# SAMA7G54D1G device description
Architecture: CORTEX-A7; Family: SAMA; Series: SAMA7G
Registers are 32-bit, read-write, reset 0x0 unless marked. A register's access mark holds for its fields unless they carry their own. Offsets are from the block's base; [hi:lo] are bit positions; {n}, {i} and the like mark numbered series.

## UHPHS — USB Host High Speed Port
Instances: UHPHS_EHCI 0x00500000
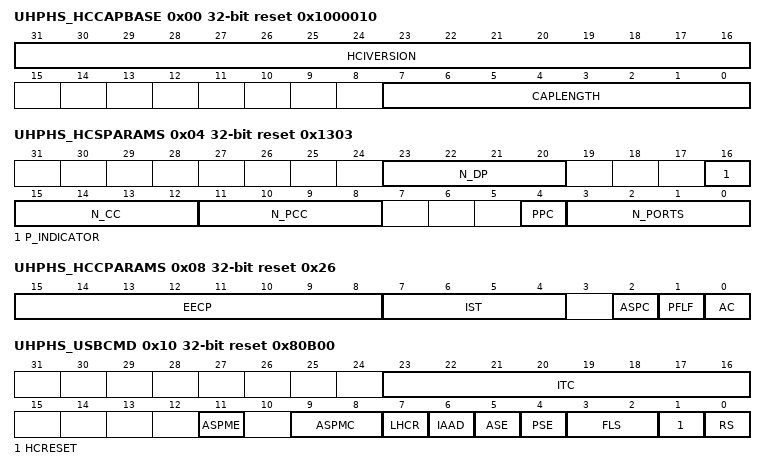
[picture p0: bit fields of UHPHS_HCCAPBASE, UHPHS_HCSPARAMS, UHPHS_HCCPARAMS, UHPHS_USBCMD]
0x00 UHPHS_HCCAPBASE ro reset 0x1000010 — UHPHS Host Controller Capability Register
  [31:16] HCIVERSION — Host Controller Interface Version Number
  [7:0] CAPLENGTH — Capability Registers Length
0x04 UHPHS_HCSPARAMS ro reset 0x1303 — UHPHS Host Controller Structural Parameters Register
  [23:20] N_DP — Debug Port Number
  [16] P_INDICATOR — Port Indicators
  [15:12] N_CC — Number of Companion Controllers
  [11:8] N_PCC — Number of Ports per Companion Controller
  [4] PPC — Port Power Control
  [3:0] N_PORTS — Number of Ports
0x08 UHPHS_HCCPARAMS ro reset 0x26 — UHPHS Host Controller Capability Parameters Register
  [15:8] EECP — EHCI Extended Capabilities Pointer
  [7:4] IST — Isochronous Scheduling Threshold
  [2] ASPC — Asynchronous Schedule Park Capability
    0=Host controller does not supports the park feature for high-speed queue; 1=Host controller supports the park feature for high-speed queue heads in the Asynchronous Schedule
  [1] PFLF — Programmable Frame List Flag
    0=System software must use a frame list length of 1024 elements with this host controller. The UHPHS_USBCMD register Frame List Size field is a read-only register and must be set to 0.; 1=System software can specify and use a smaller frame list and configure the host controller via the UHPHS_USBCMD register Frame List Size field. The frame list must always be aligned on a 4-Kbyte page boundary. This requirement ensures that the frame list is always physically contiguous.
  [0] AC — 64-bit Addressing Capability
    0=Data structures using 32-bit address memory pointers; 1=Data structures using 64-bit address memory pointers
0x10 UHPHS_USBCMD reset 0x80B00 — UHPHS USB Command Register
  [23:16] ITC — Interrupt Threshold Control (read/write)
  [11] ASPME — Asynchronous Schedule Park Mode Enable (optional) (read/write or read-only)
    0=Park mode is enabled; 1=Park mode is disabled
  [9:8] ASPMC — Asynchronous Schedule Park Mode Count (optional) (read/write or read-only)
  [7] LHCR — Light Host Controller Reset (optional) (read/write)
  [6] IAAD — Interrupt on Async Advance Doorbell (read/write)
  [5] ASE — Asynchronous Schedule Enable (read/write)
    0=Do not process the Asynchronous Schedule; 1=Use the UHPHS_ASYNCLISTADDR register to access the Asynchronous Schedule
  [4] PSE — Periodic Schedule Enable (read/write)
    0=Do not process the Periodic Schedule; 1=Use the UHPHS_PERIODICLISTBASE register to access the Periodic Schedule
  [3:2] FLS — Frame List Size (read/write or read-only)
    0=1024 elements (4096 bytes); 1=512 elements (2048 bytes); 2=256 elements (1024 bytes), for resource-constrained environments
  [1] HCRESET — Host Controller Reset (read/write)
  [0] RS — Run/Stop (read/write)
    0=Host Controller completes the current and any actively pipelined transactions on the USB and then halts; 1=Host Controller proceeds with execution of the schedule
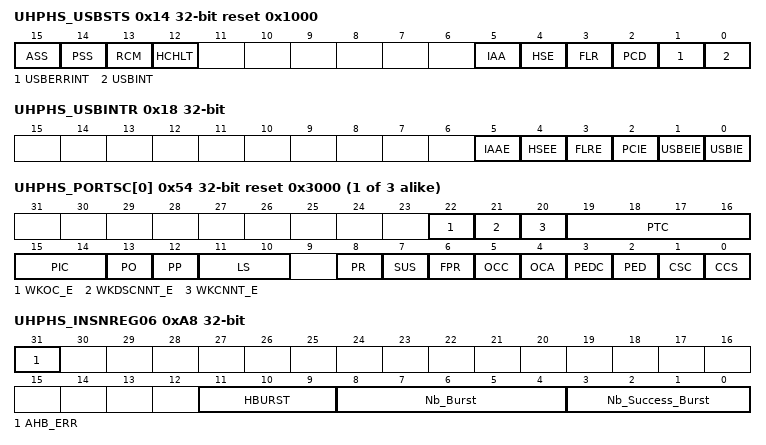
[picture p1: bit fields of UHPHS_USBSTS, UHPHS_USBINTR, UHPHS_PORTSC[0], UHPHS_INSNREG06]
0x14 UHPHS_USBSTS reset 0x1000 — UHPHS USB Status Register
  [15] ASS — Asynchronous Schedule Status (read-only)
    0=Asynchronous Schedule is disabled; 1=Asynchronous Schedule is enabled
  [14] PSS — Periodic Schedule Status (read-only)
  [13] RCM — Reclamation (read-only)
  [12] HCHLT — HCHalted (read-only)
  [5] IAA — Interrupt on Async Advance (cleared on write)
  [4] HSE — Host System Error (cleared on write)
  [3] FLR — Frame List Rollover (cleared on write)
  [2] PCD — Port Change Detect (cleared on write)
  [1] USBERRINT — USB Error Interrupt (cleared on write)
  [0] USBINT — USB Interrupt (cleared on write)
0x18 UHPHS_USBINTR — UHPHS USB Interrupt Enable Register
  [5] IAAE — Interrupt on Async Advance Enable
  [4] HSEE — Host System Error Interrupt Enable
  [3] FLRE — Frame List Rollover Interrupt Enable
  [2] PCIE — Port Change Detect Interrupt Enable
  [1] USBEIE — USBERRINT Interrupt Enable
  [0] USBIE — USBINT Interrupt Enable
0x1C UHPHS_FRINDEX — UHPHS USB Frame Index Register
  [13:0] FI — Frame Index
0x20 UHPHS_CTRLDSSEGMENT — UHPHS Control Data Structure Segment Register
0x24 UHPHS_PERIODICLISTBASE — UHPHS Periodic Frame List Base Address Register
  [31:12] BA — Base Address (Low)
0x28 UHPHS_ASYNCLISTADDR — UHPHS Asynchronous List Address Register
  [31:5] LPL — Link Pointer Low
0x50 UHPHS_CONFIGFLAG — UHPHS Configured Flag Register
  [0] CF — Configure Flag (Read/Write)
    0=Port routing control logic default-routes each port to an implementation-dependent classic host controller (default value); 1=Port routing control logic default-routes all ports to this host controller
{0x54+4i} UHPHS_PORTSC[{i}] (i=0..2) reset 0x3000 — UHPHS Port Status and Control Register (port = 0)
  [22] WKOC_E — Wake on Over-current Enable (read/write)
    0=Disables the port to be sensitive to over-current conditions as wake-up events; 1=Enables the port to be sensitive to over-current conditions as wake-up events
  [21] WKDSCNNT_E — Wake on Disconnect Enable (read/write)
    0=Disables the port to be sensitive to device disconnects as wake-up events; 1=Enables the port to be sensitive to device disconnects as wake-up events
  [20] WKCNNT_E — Wake on Connect Enable (read/write)
    0=Disables the port to be sensitive to device connects as wake-up events; 1=Enables the port to be sensitive to device connects as wake-up events
  [19:16] PTC — Port Test Control (read/write)
  [15:14] PIC — Port Indicator Control (read/write)
  [13] PO — Port Owner (read/write)
    0=This bit unconditionally goes to a 0 when the bit UHPHS_CONFIGFLAG.CF makes a 0 to 1 transition; 1=This bit unconditionally goes to 1 whenever the bit UHPHS_CONFIGFLAG.CF=0
  [12] PP — Port Power (read/write or read-only)
  [11:10] LS — Line Status (read-only)
    0=SE0 (Not a low-speed device, perform EHCI reset); 1=K_STATE (Low-speed device, release ownership of port); 2=J_STATE (Not a low-speed device, perform EHCI reset); 3=UNDEFINED (Not a low-speed device, perform EHCI reset)
  [8] PR — Port Reset (read/write)
    0=Port is not in Reset; 1=Port is in Reset
  [7] SUS — Suspend (read/write)
    0=Port not in suspend state; 1=Port in suspend state
  [6] FPR — Force Port Resume (read/write)
    0=No resume (K-state) detected/driven on port; 1=Resume detected/driven on port
  [5] OCC — Over-current Change (read/write clear)
    0=No change to Over-current Active; 1=Changes to Over-current Active
  [4] OCA — Over-current Active (read-only)
    0=This port does not have an over-current condition; 1=This port currently has an over-current condition
  [3] PEDC — Port Enable/Disable Change (read/write clear)
    0=No change in port enabled/disabled status; 1=Port enabled/disabled status has changed
  [2] PED — Port Enabled/Disabled (read/write)
    0=Disable; 1=Enable
  [1] CSC — Connect Status Change (read/write clear)
    0=No change; 1=Change in Current Connect Status
  [0] CCS — Current Connect Status (read-only)
    0=No device is present; 1=Device is present on port
0xA8 UHPHS_INSNREG06 — EHCI Specific Registers 06
  [31] AHB_ERR — AHB Error
  [11:9] HBURST — Burst Value (Read-only)
  [8:4] Nb_Burst — Number of Bursts (Read-only)
  [3:0] Nb_Success_Burst — Number of Successful Bursts (Read-only)
0xAC UHPHS_INSNREG07 — EHCI Specific Registers 07
  [31:0] AHB_ADDR — AHB Address (Read Only)
